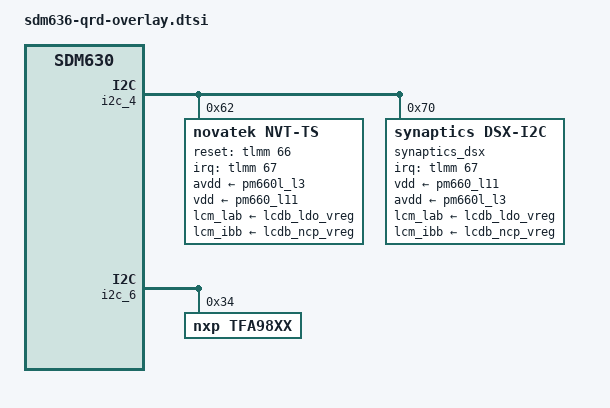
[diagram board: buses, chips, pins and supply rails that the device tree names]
/* SPDX-License-Identifier: GPL-2.0 */

#include "sdm630-qrd-overlay.dtsi"
#include "msm-pm660a-overlay.dtsi"
#include "sdm660-pinctrl-overlay.dtsi"
#include "sdm630-camera-sensor-qrd-overlay.dtsi"


&i2c_4 {
	status = "okay";

	/* Novatek device tree node */
	novatek@62 {
		compatible = "novatek,NVT-ts";
		reg = <0x62>;
		status = "ok";

		avdd-supply = <&pm660l_l3>; //VDD
		vdd-supply = <&pm660_l11>; //VDDIO
		lcm_lab-supply = <&lcdb_ldo_vreg>;
		lcm_ibb-supply = <&lcdb_ncp_vreg>;

		novatek,reset-gpio = <&tlmm 66 0x0>;
		novatek,irq-gpio = <&tlmm 67 0x0>;

		/* MP */
		novatek,mp-support-dt;

		/* MP Config */
		IC_X_CFG_SIZE = <18>;
		IC_Y_CFG_SIZE = <32>;
		IC_KEY_CFG_SIZE = <4>;
		X_Channel = <18>;
		Y_Channel = <32>;
		AIN_X = <17 16 15 14 13 12 11 10 9 8 7 6 5 4 3 2 1 0>;
		AIN_Y = <31 30 29 28 27 26 25 24 23 22 21 20 19 18 17 16 15
			 14 13 12 11 10  9  8  7  6  5  4  3  2  1  0>;
		AIN_KEY = <0  1  2  0xFF  0xFF  0xFF  0xFF  0xFF>;

		novatek-mp-criteria-5A06@5A06 {
			#address-cells = <1>;
			#size-cells = <0>;
			compatible = "novatek-mp-criteria-5A06";

			/* MP Criteria */
			PS_Config_Lmt_Short_Rawdata_P = <14008>;
			PS_Config_Lmt_Short_Rawdata_N = <11376>;
			PS_Config_Lmt_Key_Short_Rawdata_P = <20000>;
			PS_Config_Lmt_Key_Short_Rawdata_N = <11550>;
			PS_Config_Lmt_Short_Diff_P = <6300>;
			PS_Config_Lmt_Short_Diff_N = <0>;
			PS_Config_Lmt_Key_Short_Diff_P = <6300>;
			PS_Config_Lmt_Key_Short_Diff_N = <0>;
			PS_Config_Lmt_Short_Base_P = <2000>;
			PS_Config_Lmt_Short_Base_N = <(-2000)>;
			PS_Config_Lmt_Key_Short_Base_P = <2000>;
			PS_Config_Lmt_Key_Short_Base_N = <(-2000)>;

			PS_Config_Lmt_Open_Rawdata_P = <
				10466 10764 10729 10707 10681 10662 10653 10682 10703 10615 10638 10611 10594 10594 10596 10599 10613 10538
				10394 10557 10525 10507 10485 10475 10470 10494 10505 10411 10426 10403 10391 10383 10384 10382 10392 10392
				10448 10590 10560 10542 10525 10530 10513 10536 10542 10441 10455 10431 10421 10407 10409 10406 10415 10415
				10355 10506 10473 10455 10443 10438 10433 10457 10459 10384 10395 10374 10362 10358 10347 10344 10356 10341
				10389 10547 10502 10482 10475 10468 10467 10492 10492 10411 10423 10403 10391 10377 10375 10372 10396 10370
				10335 10478 10430 10413 10410 10411 10403 10429 10427 10336 10344 10323 10311 10296 10297 10291 10317 10292
				10346 10484 10436 10418 10419 10416 10415 10439 10440 10362 10373 10350 10339 10337 10326 10321 10346 10320
				10266 10388 10351 10337 10339 10336 10336 10362 10362 10267 10276 10252 10241 10231 10229 10225 10241 10223
				10287 10403 10381 10358 10361 10359 10359 10383 10383 10282 10293 10267 10254 10242 10244 10252 10252 10237
				10176 10285 10264 10243 10246 10245 10246 10272 10271 10204 10212 10185 10175 10175 10164 10172 10172 10159
				10176 10280 10258 10243 10241 10242 10247 10273 10272 10202 10211 10185 10174 10165 10164 10172 10174 10159
				10091 10188 10161 10154 10164 10154 10159 10188 10186 10104 10112 10083 10072 10062 10064 10071 10073 10060
				10084 10177 10143 10154 10147 10144 10153 10180 10178 10105 10113 10085 10074 10078 10075 10064 10081 10062
				 9984 10069 10039 10056 10038 10038 10048 10075 10074  9999 10007  9977  9966  9962  9974  9958  9980  9956
				 9992 10071 10045 10061 10057 10046 10056 10083 10081  9995 10002  9973  9961  9954  9971  9954  9980  9950
				 9875  9947  9927  9943  9929  9929  9938  9965  9962  9897  9904  9875  9864  9872  9877  9862  9891  9854
				 9849  9919  9908  9914  9914  9919  9929  9958  9958  9865  9871  9846  9839  9842  9844  9842  9878  9840
				 9742  9808  9798  9805  9814  9820  9815  9842  9844  9759  9766  9740  9748  9738  9744  9747  9787  9739
				 9713  9779  9770  9776  9775  9778  9788  9814  9815  9739  9744  9721  9720  9732  9727  9732  9772  9718
				 9594  9658  9647  9653  9649  9656  9678  9691  9693  9618  9624  9612  9600  9603  9607  9618  9659  9596
				 9574  9638  9630  9635  9643  9639  9660  9673  9674  9578  9583  9571  9564  9563  9570  9585  9625  9557
				 9442  9506  9495  9500  9500  9506  9528  9539  9540  9481  9484  9475  9467  9476  9472  9492  9534  9458
				 9401  9468  9457  9464  9461  9472  9484  9504  9504  9422  9425  9407  9411  9414  9417  9440  9483  9400
				 9280  9347  9338  9344  9356  9355  9364  9398  9383  9303  9318  9286  9295  9298  9305  9327  9370  9280
				 9225  9292  9284  9290  9291  9301  9310  9343  9330  9266  9282  9249  9259  9263  9274  9298  9339  9243
				 9101  9169  9161  9166  9166  9179  9188  9220  9206  9136  9153  9120  9130  9136  9151  9175  9216  9112
				 9062  9133  9123  9130  9141  9143  9150  9175  9165  9078  9092  9064  9076  9081  9098  9123  9164  9047
				 8861  8934  8928  8934  8936  8942  8951  8969  8973  8923  8912  8893  8903  8907  8930  8953  8992  8867
				 8810  8885  8880  8886  8884  8889  8899  8915  8924  8871  8851  8832  8842  8850  8874  8898  8936  8801
				 8699  8774  8770  8777  8783  8775  8785  8802  8808  8758  8733  8713  8721  8736  8761  8785  8820  8674
				 8652  8730  8724  8730  8721  8725  8736  8753  8755  8721  8693  8673  8692  8701  8726  8750  8786  8627
				10589 10303 10297 10302 10282 10294 10308 10329 10312 10262 10242 10216 10230 10259 10291 10320 10360  9069>;

			PS_Config_Lmt_Open_Rawdata_N = <
				8225 8368 8352 8341 8328 8319 8315 8329 8339 8297 8308 8295 8287 8286 8288 8289 8296 8259
				8190 8269 8254 8245 8234 8229 8227 8238 8244 8198 8206 8195 8189 8185 8186 8184 8189 8189
				8216 8285 8270 8262 8253 8256 8247 8259 8261 8213 8220 8208 8203 8196 8198 8196 8200 8200
				8172 8244 8228 8220 8214 8212 8209 8221 8221 8185 8191 8181 8175 8173 8167 8166 8172 8165
				8188 8264 8242 8233 8229 8226 8226 8237 8238 8199 8204 8194 8189 8182 8181 8180 8191 8179
				8162 8231 8208 8199 8198 8198 8195 8207 8206 8162 8166 8156 8150 8143 8143 8141 8153 8141
				8167 8234 8210 8202 8202 8201 8200 8212 8212 8175 8180 8169 8164 8163 8157 8155 8167 8155
				8129 8188 8170 8163 8164 8162 8162 8175 8175 8129 8134 8122 8117 8112 8111 8109 8116 8108
				8139 8195 8184 8173 8175 8174 8173 8185 8185 8136 8142 8129 8123 8117 8118 8122 8122 8115
				8085 8138 8128 8118 8119 8119 8119 8132 8131 8099 8103 8090 8085 8085 8080 8083 8083 8077
				8085 8135 8125 8117 8116 8117 8119 8132 8132 8098 8102 8090 8084 8080 8080 8083 8084 8077
				8044 8091 8078 8075 8079 8075 8077 8091 8090 8051 8054 8041 8035 8030 8031 8035 8036 8030
				8041 8086 8070 8075 8071 8070 8074 8087 8086 8051 8055 8041 8036 8038 8037 8031 8040 8031
				7993 8034 8019 8027 8019 8019 8024 8037 8036 8000 8004 7990 7984 7982 7988 7980 7991 7979
				7997 8035 8022 8030 8028 8023 8027 8041 8039 7998 8001 7987 7982 7979 7987 7978 7991 7977
				7941 7975 7966 7973 7967 7966 7971 7984 7982 7951 7954 7940 7935 7939 7941 7934 7948 7930
				7928 7962 7956 7959 7959 7962 7967 7980 7980 7935 7939 7926 7923 7925 7925 7925 7942 7923
				7877 7908 7903 7907 7911 7914 7912 7925 7926 7884 7888 7875 7879 7874 7877 7879 7898 7875
				7862 7894 7890 7893 7892 7894 7899 7911 7912 7875 7877 7866 7866 7871 7869 7871 7891 7865
				7805 7836 7831 7833 7831 7835 7846 7852 7853 7817 7819 7814 7808 7809 7811 7817 7836 7806
				7795 7826 7822 7825 7829 7827 7837 7843 7844 7797 7800 7794 7791 7790 7794 7801 7820 7787
				7732 7763 7758 7760 7760 7763 7773 7779 7779 7751 7752 7748 7744 7748 7746 7756 7776 7739
				7712 7744 7739 7743 7741 7747 7752 7762 7762 7722 7724 7715 7717 7718 7720 7731 7752 7712
				7654 7686 7682 7685 7690 7690 7694 7711 7704 7665 7672 7657 7661 7663 7666 7677 7697 7654
				7627 7660 7656 7659 7659 7664 7668 7684 7678 7647 7655 7639 7644 7646 7651 7663 7682 7636
				7568 7600 7597 7599 7599 7606 7610 7625 7618 7585 7593 7577 7582 7585 7592 7604 7623 7573
				7549 7583 7579 7582 7587 7588 7591 7603 7599 7556 7564 7550 7556 7558 7566 7579 7598 7542
				7452 7487 7484 7487 7488 7491 7495 7504 7506 7482 7477 7468 7473 7474 7485 7497 7515 7455
				7428 7464 7461 7464 7463 7466 7470 7478 7482 7457 7447 7438 7443 7447 7458 7470 7488 7423
				7374 7410 7408 7412 7415 7411 7415 7424 7426 7403 7390 7381 7385 7392 7404 7416 7433 7362
				7351 7389 7386 7389 7385 7387 7392 7400 7401 7385 7371 7361 7371 7375 7387 7399 7416 7340
				8284 8147 8143 8146 8136 8142 8149 8159 8151 8127 8117 8105 8111 8125 8141 8155 8174 7552>;

			PS_Config_Lmt_FW_Rawdata_P = <
				1200 1200 1200 1200 1200 1200 1200 1200 1200 1200 1200 1200 1200 1200 1200 1200 1200 1200
				1200 1200 1200 1200 1200 1200 1200 1200 1200 1200 1200 1200 1200 1200 1200 1200 1200 1200
				1200 1200 1200 1200 1200 1200 1200 1200 1200 1200 1200 1200 1200 1200 1200 1200 1200 1200
				1200 1200 1200 1200 1200 1200 1200 1200 1200 1200 1200 1200 1200 1200 1200 1200 1200 1200
				1200 1200 1200 1200 1200 1200 1200 1200 1200 1200 1200 1200 1200 1200 1200 1200 1200 1200
				1200 1200 1200 1200 1200 1200 1200 1200 1200 1200 1200 1200 1200 1200 1200 1200 1200 1200
				1200 1200 1200 1200 1200 1200 1200 1200 1200 1200 1200 1200 1200 1200 1200 1200 1200 1200
				1200 1200 1200 1200 1200 1200 1200 1200 1200 1200 1200 1200 1200 1200 1200 1200 1200 1200
				1200 1200 1200 1200 1200 1200 1200 1200 1200 1200 1200 1200 1200 1200 1200 1200 1200 1200
				1200 1200 1200 1200 1200 1200 1200 1200 1200 1200 1200 1200 1200 1200 1200 1200 1200 1200
				1200 1200 1200 1200 1200 1200 1200 1200 1200 1200 1200 1200 1200 1200 1200 1200 1200 1200
				1200 1200 1200 1200 1200 1200 1200 1200 1200 1200 1200 1200 1200 1200 1200 1200 1200 1200
				1200 1200 1200 1200 1200 1200 1200 1200 1200 1200 1200 1200 1200 1200 1200 1200 1200 1200
				1200 1200 1200 1200 1200 1200 1200 1200 1200 1200 1200 1200 1200 1200 1200 1200 1200 1200
				1200 1200 1200 1200 1200 1200 1200 1200 1200 1200 1200 1200 1200 1200 1200 1200 1200 1200
				1200 1200 1200 1200 1200 1200 1200 1200 1200 1200 1200 1200 1200 1200 1200 1200 1200 1200
				1200 1200 1200 1200 1200 1200 1200 1200 1200 1200 1200 1200 1200 1200 1200 1200 1200 1200
				1200 1200 1200 1200 1200 1200 1200 1200 1200 1200 1200 1200 1200 1200 1200 1200 1200 1200
				1200 1200 1200 1200 1200 1200 1200 1200 1200 1200 1200 1200 1200 1200 1200 1200 1200 1200
				1200 1200 1200 1200 1200 1200 1200 1200 1200 1200 1200 1200 1200 1200 1200 1200 1200 1200
				1200 1200 1200 1200 1200 1200 1200 1200 1200 1200 1200 1200 1200 1200 1200 1200 1200 1200
				1200 1200 1200 1200 1200 1200 1200 1200 1200 1200 1200 1200 1200 1200 1200 1200 1200 1200
				1200 1200 1200 1200 1200 1200 1200 1200 1200 1200 1200 1200 1200 1200 1200 1200 1200 1200
				1200 1200 1200 1200 1200 1200 1200 1200 1200 1200 1200 1200 1200 1200 1200 1200 1200 1200
				1200 1200 1200 1200 1200 1200 1200 1200 1200 1200 1200 1200 1200 1200 1200 1200 1200 1200
				1200 1200 1200 1200 1200 1200 1200 1200 1200 1200 1200 1200 1200 1200 1200 1200 1200 1200
				1200 1200 1200 1200 1200 1200 1200 1200 1200 1200 1200 1200 1200 1200 1200 1200 1200 1200
				1200 1200 1200 1200 1200 1200 1200 1200 1200 1200 1200 1200 1200 1200 1200 1200 1200 1200
				1200 1200 1200 1200 1200 1200 1200 1200 1200 1200 1200 1200 1200 1200 1200 1200 1200 1200
				1200 1200 1200 1200 1200 1200 1200 1200 1200 1200 1200 1200 1200 1200 1200 1200 1200 1200
				1200 1200 1200 1200 1200 1200 1200 1200 1200 1200 1200 1200 1200 1200 1200 1200 1200 1200
				1200 1200 1200 1200 1200 1200 1200 1200 1200 1200 1200 1200 1200 1200 1200 1200 1200 1200>;

			PS_Config_Lmt_FW_Rawdata_N= <
				600 600 600 600 600 600 600 600 600 600 600 600 600 600 600 600 600 600
				600 600 600 600 600 600 600 600 600 600 600 600 600 600 600 600 600 600
				600 600 600 600 600 600 600 600 600 600 600 600 600 600 600 600 600 600
				600 600 600 600 600 600 600 600 600 600 600 600 600 600 600 600 600 600
				600 600 600 600 600 600 600 600 600 600 600 600 600 600 600 600 600 600
				600 600 600 600 600 600 600 600 600 600 600 600 600 600 600 600 600 600
				600 600 600 600 600 600 600 600 600 600 600 600 600 600 600 600 600 600
				600 600 600 600 600 600 600 600 600 600 600 600 600 600 600 600 600 600
				600 600 600 600 600 600 600 600 600 600 600 600 600 600 600 600 600 600
				600 600 600 600 600 600 600 600 600 600 600 600 600 600 600 600 600 600
				600 600 600 600 600 600 600 600 600 600 600 600 600 600 600 600 600 600
				600 600 600 600 600 600 600 600 600 600 600 600 600 600 600 600 600 600
				600 600 600 600 600 600 600 600 600 600 600 600 600 600 600 600 600 600
				600 600 600 600 600 600 600 600 600 600 600 600 600 600 600 600 600 600
				600 600 600 600 600 600 600 600 600 600 600 600 600 600 600 600 600 600
				600 600 600 600 600 600 600 600 600 600 600 600 600 600 600 600 600 600
				600 600 600 600 600 600 600 600 600 600 600 600 600 600 600 600 600 600
				600 600 600 600 600 600 600 600 600 600 600 600 600 600 600 600 600 600
				600 600 600 600 600 600 600 600 600 600 600 600 600 600 600 600 600 600
				600 600 600 600 600 600 600 600 600 600 600 600 600 600 600 600 600 600
				600 600 600 600 600 600 600 600 600 600 600 600 600 600 600 600 600 600
				600 600 600 600 600 600 600 600 600 600 600 600 600 600 600 600 600 600
				600 600 600 600 600 600 600 600 600 600 600 600 600 600 600 600 600 600
				600 600 600 600 600 600 600 600 600 600 600 600 600 600 600 600 600 600
				600 600 600 600 600 600 600 600 600 600 600 600 600 600 600 600 600 600
				600 600 600 600 600 600 600 600 600 600 600 600 600 600 600 600 600 600
				600 600 600 600 600 600 600 600 600 600 600 600 600 600 600 600 600 600
				600 600 600 600 600 600 600 600 600 600 600 600 600 600 600 600 600 600
				600 600 600 600 600 600 600 600 600 600 600 600 600 600 600 600 600 600
				600 600 600 600 600 600 600 600 600 600 600 600 600 600 600 600 600 600
				600 600 600 600 600 600 600 600 600 600 600 600 600 600 600 600 600 600
				600 600 600 600 600 600 600 600 600 600 600 600 600 600 600 600 600 600>;

			PS_Config_Lmt_FW_CC_P = <116>;
			PS_Config_Lmt_FW_CC_N = <72>;
			PS_Config_Lmt_Key_FW_CC_P = <38>;
			PS_Config_Lmt_Key_FW_CC_N = <9>;

			PS_Config_Lmt_FW_CC_I_P = <25>;
			PS_Config_Lmt_FW_CC_I_N = <0>;
			PS_Config_Lmt_FW_CC_Q_P = <25>;
			PS_Config_Lmt_FW_CC_Q_N = <0>;
			PS_Config_Lmt_Key_FW_CC_I_P = <25>;
			PS_Config_Lmt_Key_FW_CC_I_N = <0>;
			PS_Config_Lmt_Key_FW_CC_Q_P = <25>;
			PS_Config_Lmt_Key_FW_CC_Q_N = <0>;

			PS_Config_Lmt_FW_Diff_P = <35>;
			PS_Config_Lmt_FW_Diff_N = <(-35)>;
			PS_Config_Lmt_Key_FW_Diff_P = <35>;
			PS_Config_Lmt_Key_FW_Diff_N = <(-35)>;

			PS_Config_Diff_Test_Frame = <50>;
		};

		novatek-mp-criteria-5A07@5A07 {
			#address-cells = <1>;
			#size-cells = <0>;
			compatible = "novatek-mp-criteria-5A07";

			/* MP Criteria */
			PS_Config_Lmt_Short_Rawdata_P = <14000>;
			PS_Config_Lmt_Short_Rawdata_N = <11000>;
			PS_Config_Lmt_Key_Short_Rawdata_P = <20000>;
			PS_Config_Lmt_Key_Short_Rawdata_N = <11550>;
			PS_Config_Lmt_Short_Diff_P = <6300>;
			PS_Config_Lmt_Short_Diff_N = <0>;
			PS_Config_Lmt_Key_Short_Diff_P = <6300>;
			PS_Config_Lmt_Key_Short_Diff_N = <0>;
			PS_Config_Lmt_Short_Base_P = <2000>;
			PS_Config_Lmt_Short_Base_N = <(-2000)>;
			PS_Config_Lmt_Key_Short_Base_P = <2000>;
			PS_Config_Lmt_Key_Short_Base_N = <(-2000)>;

			PS_Config_Lmt_Open_Rawdata_P = <
				8734 8786 8766 8737 8728 8693 8714 8726 8756 8714 8724 8707 8685 8679 8689 8708 8720 8744
				8641 8670 8652 8625 8620 8589 8608 8616 8642 8602 8599 8586 8569 8561 8571 8584 8592 8610
				8608 8619 8603 8578 8577 8560 8568 8574 8599 8543 8538 8525 8510 8502 8514 8524 8530 8550
				8597 8621 8601 8578 8581 8558 8574 8581 8606 8574 8566 8555 8537 8540 8542 8550 8557 8560
				8557 8591 8561 8537 8540 8517 8536 8544 8567 8527 8519 8509 8490 8487 8493 8502 8517 8508
				8588 8612 8581 8559 8565 8548 8562 8569 8591 8534 8524 8516 8498 8493 8500 8508 8525 8518
				8535 8559 8527 8509 8514 8498 8513 8522 8542 8507 8498 8489 8471 8478 8475 8482 8498 8489
				8543 8555 8533 8515 8519 8505 8520 8529 8549 8510 8500 8491 8474 8472 8475 8482 8491 8487
				8507 8512 8507 8479 8483 8471 8487 8493 8514 8463 8454 8446 8428 8426 8429 8448 8443 8442
				8506 8512 8506 8478 8484 8473 8489 8497 8517 8485 8474 8465 8447 8457 8450 8469 8466 8465
				8454 8459 8454 8427 8428 8423 8438 8446 8464 8429 8418 8409 8392 8394 8392 8411 8407 8404
				8468 8471 8461 8441 8452 8439 8453 8462 8475 8429 8417 8408 8392 8391 8391 8406 8407 8405
				8406 8411 8392 8389 8387 8383 8398 8405 8416 8392 8380 8373 8355 8369 8364 8362 8372 8370
				8401 8406 8388 8391 8380 8379 8394 8401 8412 8380 8369 8362 8345 8349 8358 8352 8363 8357
				8358 8362 8344 8348 8348 8334 8351 8358 8368 8327 8315 8309 8292 8294 8305 8296 8311 8304
				8345 8348 8329 8335 8328 8325 8340 8347 8358 8335 8323 8316 8300 8314 8315 8308 8323 8314
				8285 8290 8276 8269 8274 8273 8290 8296 8310 8268 8258 8251 8236 8245 8239 8246 8261 8254
				8285 8288 8273 8269 8283 8283 8288 8292 8307 8260 8251 8244 8241 8236 8233 8243 8258 8249
				8220 8223 8210 8207 8212 8212 8228 8232 8244 8216 8205 8201 8185 8203 8191 8200 8214 8204
				8204 8207 8198 8193 8194 8197 8225 8218 8229 8204 8190 8196 8170 8179 8175 8187 8200 8188
				8156 8158 8150 8147 8157 8150 8177 8171 8182 8144 8128 8133 8109 8115 8114 8125 8137 8125
				8132 8135 8128 8124 8127 8129 8155 8149 8158 8141 8125 8132 8106 8124 8112 8125 8137 8123
				8071 8076 8072 8068 8067 8072 8088 8091 8098 8074 8059 8056 8041 8053 8047 8060 8072 8056
				8059 8065 8062 8059 8067 8061 8074 8092 8085 8054 8050 8033 8022 8034 8028 8042 8054 8037
				7993 7997 7996 7994 7994 7996 8009 8027 8019 8003 8002 7983 7971 7984 7978 7993 8004 7984
				7971 7975 7977 7975 7971 7976 7989 8007 7997 7978 7976 7958 7946 7959 7953 7969 7982 7958
				7917 7922 7924 7923 7928 7923 7936 7949 7943 7914 7912 7896 7884 7897 7890 7907 7920 7892
				7878 7885 7886 7885 7879 7884 7896 7903 7910 7902 7880 7873 7862 7875 7869 7887 7901 7869
				7824 7831 7833 7832 7823 7830 7842 7848 7859 7845 7819 7812 7801 7813 7810 7827 7840 7807
				7817 7824 7827 7825 7826 7823 7833 7841 7850 7829 7803 7795 7782 7797 7796 7814 7824 7787
				7770 7778 7779 7775 7767 7774 7786 7793 7801 7790 7763 7756 7752 7756 7757 7776 7788 7751
				7819 7825 7826 7819 7804 7818 7833 7841 7832 7822 7812 7801 7787 7802 7809 7830 7843 7778>;

			PS_Config_Lmt_Open_Rawdata_N = <
				7601 7631 7620 7603 7598 7578 7590 7597 7614 7590 7596 7586 7574 7570 7576 7587 7593 7607
				7549 7565 7555 7540 7538 7520 7530 7535 7550 7527 7526 7518 7508 7504 7510 7517 7521 7532
				7530 7537 7528 7514 7513 7504 7508 7511 7525 7494 7491 7484 7475 7471 7477 7483 7487 7498
				7524 7538 7527 7514 7515 7503 7511 7516 7530 7511 7507 7501 7491 7493 7494 7498 7502 7504
				7502 7521 7504 7491 7492 7479 7490 7494 7507 7485 7481 7475 7464 7463 7466 7471 7479 7474
				7519 7533 7515 7503 7506 7497 7505 7509 7521 7489 7483 7479 7469 7466 7470 7474 7484 7480
				7490 7503 7485 7475 7478 7469 7477 7482 7494 7474 7469 7464 7453 7457 7456 7459 7469 7464
				7494 7501 7488 7478 7481 7472 7481 7486 7497 7475 7470 7465 7455 7454 7456 7459 7465 7462
				7473 7477 7474 7458 7460 7453 7462 7466 7478 7449 7444 7439 7429 7428 7430 7440 7438 7437
				7473 7477 7473 7457 7461 7455 7464 7468 7479 7461 7455 7450 7440 7446 7442 7452 7450 7450
				7444 7447 7444 7428 7429 7426 7435 7440 7450 7430 7423 7419 7409 7410 7409 7420 7418 7416
				7452 7454 7448 7436 7443 7435 7443 7448 7455 7430 7423 7418 7409 7409 7408 7417 7417 7416
				7417 7419 7409 7407 7406 7404 7412 7416 7423 7409 7402 7398 7388 7396 7393 7392 7398 7396
				7414 7417 7407 7408 7402 7401 7410 7414 7420 7402 7396 7392 7382 7385 7390 7386 7393 7389
				7390 7392 7382 7384 7384 7376 7386 7390 7396 7372 7365 7362 7352 7354 7360 7355 7364 7359
				7382 7384 7374 7377 7373 7371 7380 7384 7389 7377 7370 7366 7357 7365 7366 7362 7370 7365
				7349 7351 7343 7340 7342 7342 7351 7355 7362 7339 7334 7330 7321 7326 7323 7327 7335 7331
				7349 7350 7342 7340 7347 7348 7350 7353 7361 7335 7329 7326 7324 7321 7319 7325 7333 7328
				7312 7314 7307 7305 7308 7307 7316 7319 7326 7310 7304 7301 7292 7302 7296 7301 7309 7303
				7303 7305 7299 7297 7298 7299 7315 7311 7317 7303 7295 7299 7284 7289 7287 7293 7301 7294
				7276 7277 7273 7271 7277 7273 7288 7284 7291 7269 7260 7263 7249 7253 7252 7259 7265 7258
				7262 7264 7260 7258 7260 7261 7276 7272 7277 7268 7259 7262 7248 7258 7251 7259 7266 7258
				7228 7231 7229 7227 7226 7229 7238 7240 7244 7230 7221 7220 7211 7218 7214 7222 7229 7220
				7222 7225 7223 7221 7226 7222 7230 7240 7236 7219 7217 7207 7201 7207 7204 7212 7219 7209
				7184 7186 7186 7185 7185 7186 7193 7203 7199 7190 7189 7179 7172 7179 7176 7184 7191 7179
				7172 7174 7175 7174 7172 7175 7182 7192 7187 7176 7175 7164 7158 7165 7161 7171 7178 7164
				7141 7145 7145 7145 7148 7145 7152 7159 7156 7140 7138 7129 7123 7130 7126 7136 7143 7127
				7120 7123 7124 7123 7120 7123 7130 7133 7137 7133 7121 7116 7111 7118 7115 7125 7132 7115
				7089 7093 7094 7094 7088 7093 7099 7103 7109 7101 7087 7083 7076 7083 7081 7091 7098 7079
				7085 7089 7091 7090 7090 7088 7094 7099 7104 7092 7078 7073 7066 7074 7073 7083 7089 7069
				7059 7063 7064 7062 7057 7061 7068 7072 7076 7070 7055 7051 7048 7051 7052 7062 7069 7048
				7086 7090 7091 7086 7078 7086 7094 7099 7094 7088 7082 7076 7068 7077 7081 7092 7100 7063>;

			PS_Config_Lmt_FW_Rawdata_P = <
				1500 1500 1500 1500 1500 1500 1500 1500 1500 1500 1500 1500 1500 1500 1500 1500 1500 1500
				1500 1500 1500 1500 1500 1500 1500 1500 1500 1500 1500 1500 1500 1500 1500 1500 1500 1500
				1500 1500 1500 1500 1500 1500 1500 1500 1500 1500 1500 1500 1500 1500 1500 1500 1500 1500
				1500 1500 1500 1500 1500 1500 1500 1500 1500 1500 1500 1500 1500 1500 1500 1500 1500 1500
				1500 1500 1500 1500 1500 1500 1500 1500 1500 1500 1500 1500 1500 1500 1500 1500 1500 1500
				1500 1500 1500 1500 1500 1500 1500 1500 1500 1500 1500 1500 1500 1500 1500 1500 1500 1500
				1500 1500 1500 1500 1500 1500 1500 1500 1500 1500 1500 1500 1500 1500 1500 1500 1500 1500
				1500 1500 1500 1500 1500 1500 1500 1500 1500 1500 1500 1500 1500 1500 1500 1500 1500 1500
				1500 1500 1500 1500 1500 1500 1500 1500 1500 1500 1500 1500 1500 1500 1500 1500 1500 1500
				1500 1500 1500 1500 1500 1500 1500 1500 1500 1500 1500 1500 1500 1500 1500 1500 1500 1500
				1500 1500 1500 1500 1500 1500 1500 1500 1500 1500 1500 1500 1500 1500 1500 1500 1500 1500
				1500 1500 1500 1500 1500 1500 1500 1500 1500 1500 1500 1500 1500 1500 1500 1500 1500 1500
				1500 1500 1500 1500 1500 1500 1500 1500 1500 1500 1500 1500 1500 1500 1500 1500 1500 1500
				1500 1500 1500 1500 1500 1500 1500 1500 1500 1500 1500 1500 1500 1500 1500 1500 1500 1500
				1500 1500 1500 1500 1500 1500 1500 1500 1500 1500 1500 1500 1500 1500 1500 1500 1500 1500
				1500 1500 1500 1500 1500 1500 1500 1500 1500 1500 1500 1500 1500 1500 1500 1500 1500 1500
				1500 1500 1500 1500 1500 1500 1500 1500 1500 1500 1500 1500 1500 1500 1500 1500 1500 1500
				1500 1500 1500 1500 1500 1500 1500 1500 1500 1500 1500 1500 1500 1500 1500 1500 1500 1500
				1500 1500 1500 1500 1500 1500 1500 1500 1500 1500 1500 1500 1500 1500 1500 1500 1500 1500
				1500 1500 1500 1500 1500 1500 1500 1500 1500 1500 1500 1500 1500 1500 1500 1500 1500 1500
				1500 1500 1500 1500 1500 1500 1500 1500 1500 1500 1500 1500 1500 1500 1500 1500 1500 1500
				1500 1500 1500 1500 1500 1500 1500 1500 1500 1500 1500 1500 1500 1500 1500 1500 1500 1500
				1500 1500 1500 1500 1500 1500 1500 1500 1500 1500 1500 1500 1500 1500 1500 1500 1500 1500
				1500 1500 1500 1500 1500 1500 1500 1500 1500 1500 1500 1500 1500 1500 1500 1500 1500 1500
				1500 1500 1500 1500 1500 1500 1500 1500 1500 1500 1500 1500 1500 1500 1500 1500 1500 1500
				1500 1500 1500 1500 1500 1500 1500 1500 1500 1500 1500 1500 1500 1500 1500 1500 1500 1500
				1500 1500 1500 1500 1500 1500 1500 1500 1500 1500 1500 1500 1500 1500 1500 1500 1500 1500
				1500 1500 1500 1500 1500 1500 1500 1500 1500 1500 1500 1500 1500 1500 1500 1500 1500 1500
				1500 1500 1500 1500 1500 1500 1500 1500 1500 1500 1500 1500 1500 1500 1500 1500 1500 1500
				1500 1500 1500 1500 1500 1500 1500 1500 1500 1500 1500 1500 1500 1500 1500 1500 1500 1500
				1500 1500 1500 1500 1500 1500 1500 1500 1500 1500 1500 1500 1500 1500 1500 1500 1500 1500
				1500 1500 1500 1500 1500 1500 1500 1500 1500 1500 1500 1500 1500 1500 1500 1500 1500 1500 >;

			PS_Config_Lmt_FW_Rawdata_N= <
				800 800 800 800 800 800 800 800 800 800 800 800 800 800 800 800 800 800
				800 800 800 800 800 800 800 800 800 800 800 800 800 800 800 800 800 800
				800 800 800 800 800 800 800 800 800 800 800 800 800 800 800 800 800 800
				800 800 800 800 800 800 800 800 800 800 800 800 800 800 800 800 800 800
				800 800 800 800 800 800 800 800 800 800 800 800 800 800 800 800 800 800
				800 800 800 800 800 800 800 800 800 800 800 800 800 800 800 800 800 800
				800 800 800 800 800 800 800 800 800 800 800 800 800 800 800 800 800 800
				800 800 800 800 800 800 800 800 800 800 800 800 800 800 800 800 800 800
				800 800 800 800 800 800 800 800 800 800 800 800 800 800 800 800 800 800
				800 800 800 800 800 800 800 800 800 800 800 800 800 800 800 800 800 800
				800 800 800 800 800 800 800 800 800 800 800 800 800 800 800 800 800 800
				800 800 800 800 800 800 800 800 800 800 800 800 800 800 800 800 800 800
				800 800 800 800 800 800 800 800 800 800 800 800 800 800 800 800 800 800
				800 800 800 800 800 800 800 800 800 800 800 800 800 800 800 800 800 800
				800 800 800 800 800 800 800 800 800 800 800 800 800 800 800 800 800 800
				800 800 800 800 800 800 800 800 800 800 800 800 800 800 800 800 800 800
				800 800 800 800 800 800 800 800 800 800 800 800 800 800 800 800 800 800
				800 800 800 800 800 800 800 800 800 800 800 800 800 800 800 800 800 800
				800 800 800 800 800 800 800 800 800 800 800 800 800 800 800 800 800 800
				800 800 800 800 800 800 800 800 800 800 800 800 800 800 800 800 800 800
				800 800 800 800 800 800 800 800 800 800 800 800 800 800 800 800 800 800
				800 800 800 800 800 800 800 800 800 800 800 800 800 800 800 800 800 800
				800 800 800 800 800 800 800 800 800 800 800 800 800 800 800 800 800 800
				800 800 800 800 800 800 800 800 800 800 800 800 800 800 800 800 800 800
				800 800 800 800 800 800 800 800 800 800 800 800 800 800 800 800 800 800
				800 800 800 800 800 800 800 800 800 800 800 800 800 800 800 800 800 800
				800 800 800 800 800 800 800 800 800 800 800 800 800 800 800 800 800 800
				800 800 800 800 800 800 800 800 800 800 800 800 800 800 800 800 800 800
				800 800 800 800 800 800 800 800 800 800 800 800 800 800 800 800 800 800
				800 800 800 800 800 800 800 800 800 800 800 800 800 800 800 800 800 800
				800 800 800 800 800 800 800 800 800 800 800 800 800 800 800 800 800 800
				800 800 800 800 800 800 800 800 800 800 800 800 800 800 800 800 800 800 >;

			PS_Config_Lmt_FW_CC_P = <115>;
			PS_Config_Lmt_FW_CC_N = <69>;
			PS_Config_Lmt_Key_FW_CC_P = <38>;
			PS_Config_Lmt_Key_FW_CC_N = <9>;

			PS_Config_Lmt_FW_CC_I_P = <25>;
			PS_Config_Lmt_FW_CC_I_N = <0>;
			PS_Config_Lmt_FW_CC_Q_P = <25>;
			PS_Config_Lmt_FW_CC_Q_N = <0>;
			PS_Config_Lmt_Key_FW_CC_I_P = <25>;
			PS_Config_Lmt_Key_FW_CC_I_N = <0>;
			PS_Config_Lmt_Key_FW_CC_Q_P = <25>;
			PS_Config_Lmt_Key_FW_CC_Q_N = <0>;

			PS_Config_Lmt_FW_Diff_P = <35>;
			PS_Config_Lmt_FW_Diff_N = <(-35)>;
			PS_Config_Lmt_Key_FW_Diff_P = <35>;
			PS_Config_Lmt_Key_FW_Diff_N = <(-35)>;

			PS_Config_Diff_Test_Frame = <50>;
		};
	};

	synaptics_dsx@70 {
			compatible = "synaptics,dsx-i2c";
			reg = <0x70>;
			interrupt-parent = <&tlmm>;
			vdd-supply = <&pm660_l11>;
			avdd-supply = <&pm660l_l3>;
			lcm_lab-supply = <&lcdb_ldo_vreg>;
			lcm_ibb-supply = <&lcdb_ncp_vreg>;
			synaptics,pwr-reg-name = "avdd";
			synaptics,bus-reg-name = "vdd";
			synaptics,ub-i2c-addr = <0x2c>;
			synaptics,irq-gpio = <&tlmm 67 0x2008>; /* IRQF_ONESHOT | IRQF_TRIGGER_LOW */
			synaptics,irq-on-state = <0>;
			synaptics,power-delay-ms = <200>;
			synaptics,reset-delay-ms = <200>;
			synaptics,reset-on-state = <0>;
			synaptics,reset-active-ms = <20>;
	};
};

&i2c_6 {
	status = "okay";
	tfa98xx@34 {
		compatible = "nxp,tfa98xx";
		reg = <0x34>;
	};
};
